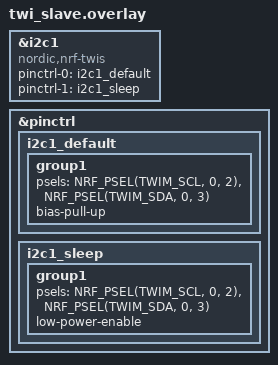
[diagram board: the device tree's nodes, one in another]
// To get started, press Ctrl+Space to bring up the completion menu and view the available nodes.

// You can also use the buttons in the sidebar to perform actions on nodes.
// Actions currently available include:

// * Enabling / disabling the node
// * Adding the bus to a bus
// * Removing the node
// * Connecting ADC channels

// For more help, browse the DeviceTree documentation at https://docs.zephyrproject.org/latest/guides/dts/index.html
// You can also visit the nRF DeviceTree extension documentation at https://docs.nordicsemi.com/bundle/nrf-connect-vscode/page/guides/ncs_configure_app.html#devicetree-support-in-the-extension

twi_slave:  &i2c1 {
	status = "okay";
	compatible = "nordic,nrf-twis";
	pinctrl-0 = <&i2c1_default>;
	pinctrl-1 = <&i2c1_sleep>;
	pinctrl-names = "default", "sleep";
};

&pinctrl {
	i2c1_default: i2c1_default {
		group1 {
			psels = <NRF_PSEL(TWIM_SCL, 0, 2)>,
				<NRF_PSEL(TWIM_SDA, 0, 3)>;
			bias-pull-up;
		};
	};

	i2c1_sleep: i2c1_sleep {
		group1 {
			psels = <NRF_PSEL(TWIM_SCL, 0, 2)>,
				<NRF_PSEL(TWIM_SDA, 0, 3)>;
			low-power-enable;
		};
	};
};
